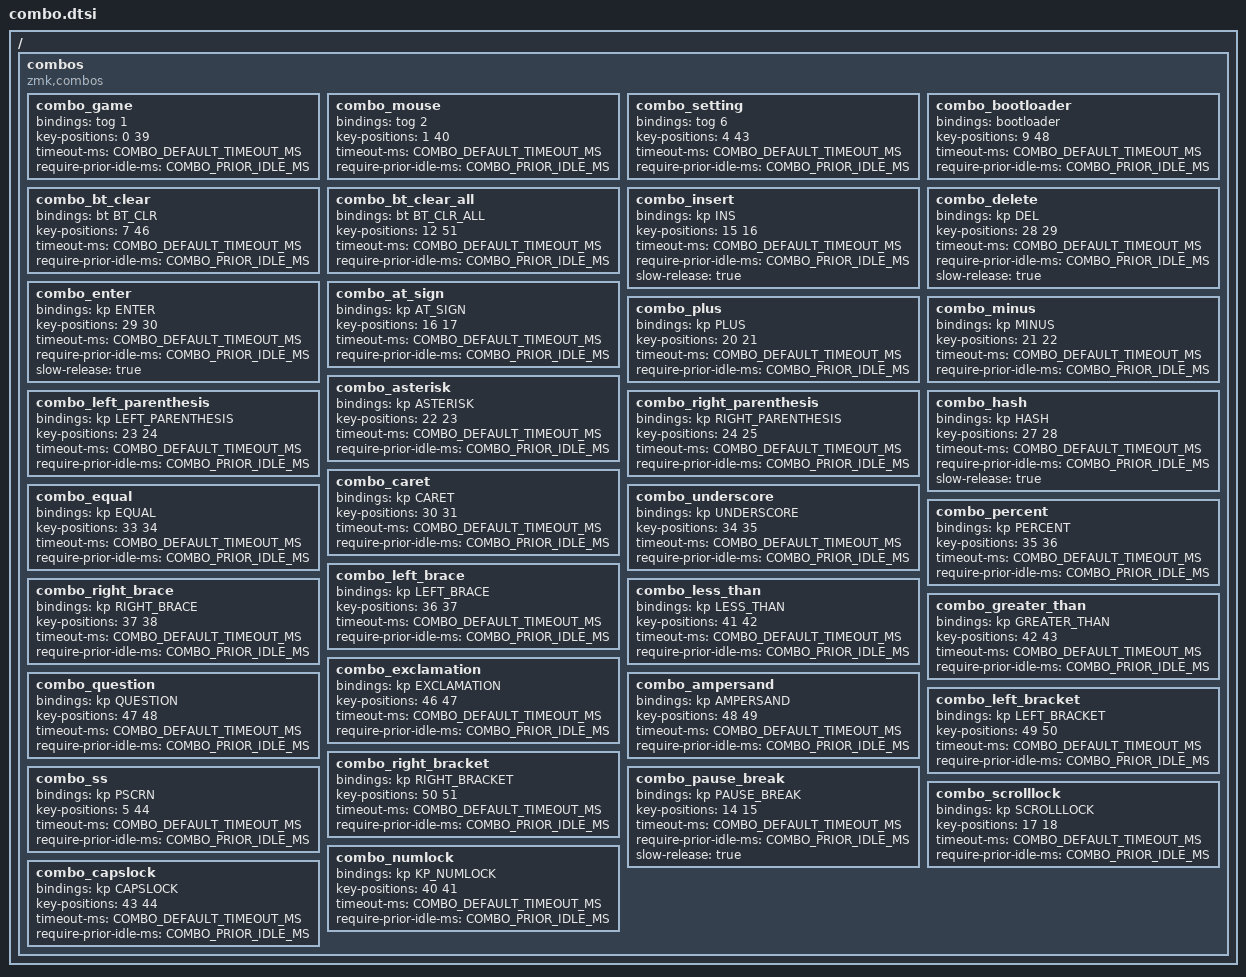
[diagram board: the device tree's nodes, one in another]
#define COMBO_DEFAULT_TIMEOUT_MS 15
#define COMBO_QUICK_TIMEOUT_MS 10
#define COMBO_PRIOR_IDLE_MS 125

/ {
    combos {
        compatible = "zmk,combos";

        combo_game {
            bindings = <&tog 1>;
            key-positions = <0 39>;
            timeout-ms = <COMBO_DEFAULT_TIMEOUT_MS>;
            require-prior-idle-ms = <COMBO_PRIOR_IDLE_MS>;
        };

        combo_mouse {
            bindings = <&tog 2>;
            key-positions = <1 40>;
            timeout-ms = <COMBO_DEFAULT_TIMEOUT_MS>;
            require-prior-idle-ms = <COMBO_PRIOR_IDLE_MS>;
        };

        combo_setting {
            bindings = <&tog 6>;
            key-positions = <4 43>;
            timeout-ms = <COMBO_DEFAULT_TIMEOUT_MS>;
            require-prior-idle-ms = <COMBO_PRIOR_IDLE_MS>;
        };

        combo_bootloader {
            bindings = <&bootloader>;
            key-positions = <9 48>;
            timeout-ms = <COMBO_DEFAULT_TIMEOUT_MS>;
            require-prior-idle-ms = <COMBO_PRIOR_IDLE_MS>;
        };

        combo_bt_clear {
            bindings = <&bt BT_CLR>;
            key-positions = <7 46>;
            timeout-ms = <COMBO_DEFAULT_TIMEOUT_MS>;
            require-prior-idle-ms = <COMBO_PRIOR_IDLE_MS>;
        };

        combo_bt_clear_all {
            bindings = <&bt BT_CLR_ALL>;
            key-positions = <12 51>;
            timeout-ms = <COMBO_DEFAULT_TIMEOUT_MS>;
            require-prior-idle-ms = <COMBO_PRIOR_IDLE_MS>;
        };

        combo_insert {
            bindings = <&kp INS>;
            key-positions = <15 16>;
            timeout-ms = <COMBO_DEFAULT_TIMEOUT_MS>;
            require-prior-idle-ms = <COMBO_PRIOR_IDLE_MS>;
            slow-release = <true>;
        };

        combo_delete {
            bindings = <&kp DEL>;
            key-positions = <28 29>;
            timeout-ms = <COMBO_DEFAULT_TIMEOUT_MS>;
            require-prior-idle-ms = <COMBO_PRIOR_IDLE_MS>;
            slow-release = <true>;
        };

        combo_enter {
            bindings = <&kp ENTER>;
            key-positions = <29 30>;
            timeout-ms = <COMBO_DEFAULT_TIMEOUT_MS>;
            require-prior-idle-ms = <COMBO_PRIOR_IDLE_MS>;
            slow-release = <true>;
        };

        combo_at_sign {
            bindings = <&kp AT_SIGN>;
            key-positions = <16 17>;
            timeout-ms = <COMBO_DEFAULT_TIMEOUT_MS>;
            require-prior-idle-ms = <COMBO_PRIOR_IDLE_MS>;
        };

        combo_plus {
            bindings = <&kp PLUS>;
            key-positions = <20 21>;
            timeout-ms = <COMBO_DEFAULT_TIMEOUT_MS>;
            require-prior-idle-ms = <COMBO_PRIOR_IDLE_MS>;
        };

        combo_minus {
            bindings = <&kp MINUS>;
            key-positions = <21 22>;
            timeout-ms = <COMBO_DEFAULT_TIMEOUT_MS>;
            require-prior-idle-ms = <COMBO_PRIOR_IDLE_MS>;
        };

        combo_asterisk {
            bindings = <&kp ASTERISK>;
            key-positions = <22 23>;
            timeout-ms = <COMBO_DEFAULT_TIMEOUT_MS>;
            require-prior-idle-ms = <COMBO_PRIOR_IDLE_MS>;
        };

        combo_left_parenthesis {
            bindings = <&kp LEFT_PARENTHESIS>;
            key-positions = <23 24>;
            timeout-ms = <COMBO_DEFAULT_TIMEOUT_MS>;
            require-prior-idle-ms = <COMBO_PRIOR_IDLE_MS>;
        };

        combo_right_parenthesis {
            bindings = <&kp RIGHT_PARENTHESIS>;
            key-positions = <24 25>;
            timeout-ms = <COMBO_DEFAULT_TIMEOUT_MS>;
            require-prior-idle-ms = <COMBO_PRIOR_IDLE_MS>;
        };

        combo_hash {
            bindings = <&kp HASH>;
            key-positions = <27 28>;
            timeout-ms = <COMBO_DEFAULT_TIMEOUT_MS>;
            require-prior-idle-ms = <COMBO_PRIOR_IDLE_MS>;
            slow-release = <true>;
        };

        combo_caret {
            bindings = <&kp CARET>;
            key-positions = <30 31>;
            timeout-ms = <COMBO_DEFAULT_TIMEOUT_MS>;
            require-prior-idle-ms = <COMBO_PRIOR_IDLE_MS>;
        };

        combo_equal {
            bindings = <&kp EQUAL>;
            key-positions = <33 34>;
            timeout-ms = <COMBO_DEFAULT_TIMEOUT_MS>;
            require-prior-idle-ms = <COMBO_PRIOR_IDLE_MS>;
        };

        combo_underscore {
            bindings = <&kp UNDERSCORE>;
            key-positions = <34 35>;
            timeout-ms = <COMBO_DEFAULT_TIMEOUT_MS>;
            require-prior-idle-ms = <COMBO_PRIOR_IDLE_MS>;
        };

        combo_percent {
            bindings = <&kp PERCENT>;
            key-positions = <35 36>;
            timeout-ms = <COMBO_DEFAULT_TIMEOUT_MS>;
            require-prior-idle-ms = <COMBO_PRIOR_IDLE_MS>;
        };

        combo_left_brace {
            bindings = <&kp LEFT_BRACE>;
            key-positions = <36 37>;
            timeout-ms = <COMBO_DEFAULT_TIMEOUT_MS>;
            require-prior-idle-ms = <COMBO_PRIOR_IDLE_MS>;
        };

        combo_right_brace {
            bindings = <&kp RIGHT_BRACE>;
            key-positions = <37 38>;
            timeout-ms = <COMBO_DEFAULT_TIMEOUT_MS>;
            require-prior-idle-ms = <COMBO_PRIOR_IDLE_MS>;
        };

        combo_less_than {
            bindings = <&kp LESS_THAN>;
            key-positions = <41 42>;
            timeout-ms = <COMBO_DEFAULT_TIMEOUT_MS>;
            require-prior-idle-ms = <COMBO_PRIOR_IDLE_MS>;
        };

        combo_greater_than {
            bindings = <&kp GREATER_THAN>;
            key-positions = <42 43>;
            timeout-ms = <COMBO_DEFAULT_TIMEOUT_MS>;
            require-prior-idle-ms = <COMBO_PRIOR_IDLE_MS>;
        };

        combo_exclamation {
            bindings = <&kp EXCLAMATION>;
            key-positions = <46 47>;
            timeout-ms = <COMBO_DEFAULT_TIMEOUT_MS>;
            require-prior-idle-ms = <COMBO_PRIOR_IDLE_MS>;
        };

        combo_question {
            bindings = <&kp QUESTION>;
            key-positions = <47 48>;
            timeout-ms = <COMBO_DEFAULT_TIMEOUT_MS>;
            require-prior-idle-ms = <COMBO_PRIOR_IDLE_MS>;
        };

        combo_ampersand {
            bindings = <&kp AMPERSAND>;
            key-positions = <48 49>;
            timeout-ms = <COMBO_DEFAULT_TIMEOUT_MS>;
            require-prior-idle-ms = <COMBO_PRIOR_IDLE_MS>;
        };

        combo_left_bracket {
            bindings = <&kp LEFT_BRACKET>;
            key-positions = <49 50>;
            timeout-ms = <COMBO_DEFAULT_TIMEOUT_MS>;
            require-prior-idle-ms = <COMBO_PRIOR_IDLE_MS>;
        };

        combo_right_bracket {
            bindings = <&kp RIGHT_BRACKET>;
            key-positions = <50 51>;
            timeout-ms = <COMBO_DEFAULT_TIMEOUT_MS>;
            require-prior-idle-ms = <COMBO_PRIOR_IDLE_MS>;
        };

        combo_ss {
            bindings = <&kp PSCRN>;
            key-positions = <5 44>;
            timeout-ms = <COMBO_DEFAULT_TIMEOUT_MS>;
            require-prior-idle-ms = <COMBO_PRIOR_IDLE_MS>;
        };

        combo_pause_break {
            bindings = <&kp PAUSE_BREAK>;
            key-positions = <14 15>;
            timeout-ms = <COMBO_DEFAULT_TIMEOUT_MS>;
            require-prior-idle-ms = <COMBO_PRIOR_IDLE_MS>;
            slow-release = <true>;
        };

        combo_scrolllock {
            bindings = <&kp SCROLLLOCK>;
            key-positions = <17 18>;
            timeout-ms = <COMBO_DEFAULT_TIMEOUT_MS>;
            require-prior-idle-ms = <COMBO_PRIOR_IDLE_MS>;
        };

        combo_numlock {
            bindings = <&kp KP_NUMLOCK>;
            key-positions = <40 41>;
            timeout-ms = <COMBO_DEFAULT_TIMEOUT_MS>;
            require-prior-idle-ms = <COMBO_PRIOR_IDLE_MS>;
        };

        combo_capslock {
            bindings = <&kp CAPSLOCK>;
            key-positions = <43 44>;
            timeout-ms = <COMBO_DEFAULT_TIMEOUT_MS>;
            require-prior-idle-ms = <COMBO_PRIOR_IDLE_MS>;
        };
    };
};
